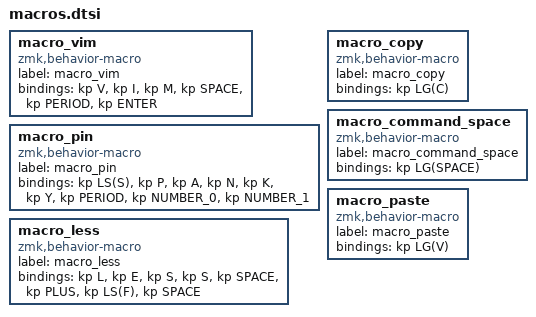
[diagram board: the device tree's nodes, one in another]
macro_vim: macro_vim{
compatible = "zmk,behavior-macro";
label = "macro_vim";
#binding-cells = <0>;
bindings = <&kp V>, <&kp I>, <&kp M>, <&kp SPACE>, <&kp PERIOD>, <&kp ENTER>;
};
macro_pin: macro_pin{
compatible = "zmk,behavior-macro";
label = "macro_pin";
#binding-cells = <0>;
bindings = <&kp LS(S)>, <&kp P>, <&kp A>, <&kp N>, <&kp K>, <&kp Y>, <&kp PERIOD>, <&kp NUMBER_0>, <&kp NUMBER_1>;
};
macro_copy: macro_copy{
compatible = "zmk,behavior-macro";
label = "macro_copy";
#binding-cells = <0>;
bindings = <&kp LG(C)>;
};
macro_less: macro_less{
compatible = "zmk,behavior-macro";
label = "macro_less";
#binding-cells = <0>;
bindings = <&kp L>, <&kp E>, <&kp S>, <&kp S>, <&kp SPACE>, <&kp PLUS>, <&kp LS(F)>, <&kp SPACE>;
};
macro_command_space: macro_command_space{
compatible = "zmk,behavior-macro";
label = "macro_command_space";
#binding-cells = <0>;
bindings = <&kp LG(SPACE)>;
};
macro_paste: macro_paste{
compatible = "zmk,behavior-macro";
label = "macro_paste";
#binding-cells = <0>;
bindings = <&kp LG(V)>;
};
